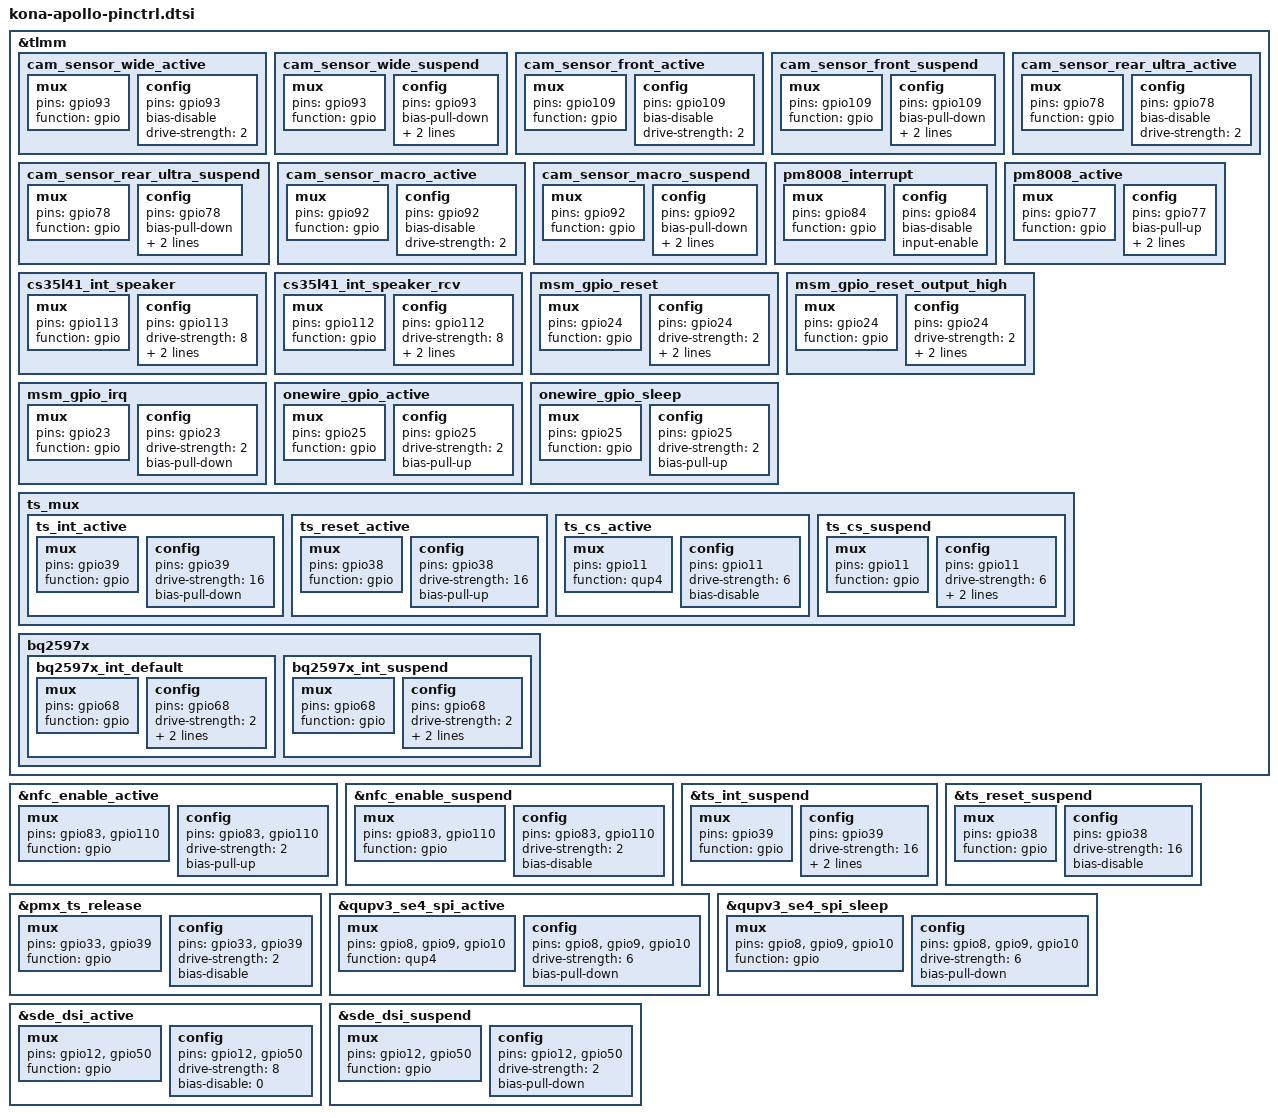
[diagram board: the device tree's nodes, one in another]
// SPDX-License-Identifier: GPL-2.0
/* Copyright (c) 2022, The Linux Foundation. All rights reserved.
 *
 * This program is free software; you can redistribute it and/or modify
 * it under the terms of the GNU General Public License version 2 and
 * only version 2 as published by the Free Software Foundation.
 *
 * This program is distributed in the hope that it will be useful,
 * but WITHOUT ANY WARRANTY; without even the implied warranty of
 * MERCHANTABILITY or FITNESS FOR A PARTICULAR PURPOSE.  See the
 * GNU General Public License for more details.
 */

&tlmm {
	cam_sensor_wide_active: cam_sensor_wide_active {
		/* RESET WIDE */
		mux {
			pins = "gpio93";
			function = "gpio";
		};

		config {
			pins = "gpio93";
			bias-disable; /* No PULL */
			drive-strength = <2>; /* 2 MA */
		};
	};

	cam_sensor_wide_suspend: cam_sensor_wide_suspend {
		mux {
			pins = "gpio93";
			function = "gpio";
		};

		config {
			pins = "gpio93";
			bias-pull-down; /* PULL DOWN */
			drive-strength = <2>; /* 2 MA */
			output-low;
		};
	};

	cam_sensor_front_active: cam_sensor_front_active {
		/* RESET FRONT */
		mux {
			pins = "gpio109";
			function = "gpio";
		};

		config {
			pins = "gpio109";
			bias-disable; /* No PULL */
			drive-strength = <2>; /* 2 MA */
		};
	};

	cam_sensor_front_suspend: cam_sensor_front_suspend {
		mux {
			pins = "gpio109";
			function = "gpio";
		};

		config {
			pins = "gpio109";
			bias-pull-down; /* PULL DOWN */
			drive-strength = <2>; /* 2 MA */
			output-low;
		};
	};

	cam_sensor_rear_ultra_active: cam_sensor_rear_ultra_active {
		/* RESET REAR ULTRA */
		mux {
			pins = "gpio78";
			function = "gpio";
		};

		config {
			pins = "gpio78";
			bias-disable; /* No PULL */
			drive-strength = <2>; /* 2 MA */
		};
	};

	cam_sensor_rear_ultra_suspend: cam_sensor_rear_ultra_suspend {
		mux {
			pins = "gpio78";
			function = "gpio";
		};

		config {
			pins = "gpio78";
			bias-pull-down; /* PULL DOWN */
			drive-strength = <2>; /* 2 MA */
			output-low;
		};
	};

	cam_sensor_macro_active: cam_sensor_macro_active {
		/* RESET MACRO */
		mux {
			pins = "gpio92";
			function = "gpio";
		};

		config {
			pins = "gpio92";
			bias-disable; /* No PULL */
			drive-strength = <2>; /* 2 MA */
		};
	};

	cam_sensor_macro_suspend: cam_sensor_macro_suspend {
		mux {
			pins = "gpio92";
			function = "gpio";
		};

		config {
			pins = "gpio92";
			bias-pull-down; /* PULL DOWN */
			drive-strength = <2>; /* 2 MA */
			output-low;
		};
	};

	pm8008_interrupt: pm8008_interrupt {
		mux {
			pins = "gpio84";
			function = "gpio";
		};

		config {
			pins = "gpio84";
			bias-disable;
			input-enable;
		};
	};

	pm8008_active: pm8008_active {
		mux {
			pins = "gpio77";
			function = "gpio";
		};

		config {
			pins = "gpio77";
			bias-pull-up;
			output-high;
			drive-strength = <2>;
		};
	};

	cs35l41_int_speaker: cs35l41_int_speaker {
		mux {
			pins = "gpio113";
			function = "gpio";
		};
		config {
			pins = "gpio113";
			drive-strength = <8>;   /* 8 mA */
			bias-disable;           /* NO PULL */
			output-high;
		};
	};

	cs35l41_int_speaker_rcv: cs35l41_int_speaker_rcv {
		mux {
			pins = "gpio112";
			function = "gpio";
		};
		config {
			pins = "gpio112";
			drive-strength = <8>;   /* 8 mA */
			bias-disable;           /* NO PULL */
			output-high;
		};
	};

	msm_gpio_reset: msm_gpio_reset {
		mux {
			pins = "gpio24";
			function = "gpio";
		};
		config {
			pins = "gpio24";
			drive-strength = <2>;
			bias-disable;
			output-low;
		};
	};

	msm_gpio_reset_output_high: msm_gpio_reset_output_high {
		mux {
			pins = "gpio24";
			function = "gpio";
		};
		config {
			pins = "gpio24";
			drive-strength = <2>;
			bias-disable;
			output-high;
		};
	};

	msm_gpio_irq: msm_gpio_irq {
		mux {
			pins = "gpio23";
			function = "gpio";
		};
		config {
			pins = "gpio23";
			drive-strength = <2>;
			bias-pull-down;
		};
	};

	onewire_gpio_active: onewire_gpio_active {
		mux {
			pins = "gpio25";
			function = "gpio";
		};

		config {
			pins = "gpio25";
			drive-strength = <2>;
			bias-pull-up; /* No PULL */
		};
	};

	onewire_gpio_sleep: onewire_gpio_sleep {
		mux {
			pins = "gpio25";
			function = "gpio";
		};

		config {
			pins = "gpio25";
			drive-strength = <2>;
			bias-pull-up; /* No PULL */
		};
	};

	ts_mux {
		ts_int_active: ts_int_active {
			mux {
				pins = "gpio39";
				function = "gpio";
			};

			config {
				pins = "gpio39";
				drive-strength = <16>;
				bias-pull-down;
			};
		};

		ts_reset_active: ts_reset_active {
			mux {
				pins = "gpio38";
				function = "gpio";
			};

			config {
				pins = "gpio38";
				drive-strength = <16>;
				bias-pull-up;
			};
		};

		ts_cs_active: ts_cs_active {
			mux {
				pins = "gpio11";
				function = "qup4";
			};

			config {
				pins = "gpio11";
				drive-strength = <6>;
				bias-disable;
			};
		};

		ts_cs_suspend: ts_cs_suspend {
			mux {
				pins = "gpio11";
				function = "gpio";
			};

			config {
				pins = "gpio11";
				drive-strength = <6>;
				bias-pull-down;
				output-low;
			};
		};
	};

	bq2597x {
		bq2597x_int_default: bq2597x_int_default {
			mux {
				pins = "gpio68";
				function = "gpio";
			};

			config {
				pins = "gpio68";
				drive-strength = <2>; /* 2 MA */
				bias-pull-up;
				input-enable;
			};
		};

		bq2597x_int_suspend: bq2597x_int_suspend {
			mux {
				pins = "gpio68";
				function = "gpio";
			};

			config {
				pins = "gpio68";
				drive-strength = <2>; /* 2 MA */
				bias-pull-up;
				input-enable;
			};
		};
	};
};

&nfc_enable_active {
	mux {
		pins = "gpio83", "gpio110";
		function = "gpio";
	};

	config {
		pins = "gpio83", "gpio110";
		drive-strength = <2>;
		bias-pull-up;
	};
};

&nfc_enable_suspend {
	mux {
		pins = "gpio83", "gpio110";
		function = "gpio";
	};

	config {
		pins = "gpio83", "gpio110";
		drive-strength = <2>;
		bias-disable;
	};
};

&ts_int_suspend {
	mux {
		pins = "gpio39";
		function = "gpio";
	};

	config {
		pins = "gpio39";
		drive-strength = <16>;
		bias-disable;
		input-enable;
	};
};

&ts_reset_suspend {
	mux {
		pins = "gpio38";
		function = "gpio";
	};

	config {
		pins = "gpio38";
		drive-strength = <16>;
		bias-disable;
	};
};

&pmx_ts_release {
	mux {
		pins = "gpio33", "gpio39";
		function = "gpio";
	};

	config {
		pins = "gpio33", "gpio39";
		drive-strength = <2>;
		bias-disable;
	};
};

&qupv3_se4_spi_active {
	mux {
		pins = "gpio8", "gpio9", "gpio10";
		function = "qup4";
	};

	config {
		pins = "gpio8", "gpio9", "gpio10";
		drive-strength = <6>;
		bias-pull-down;
	};
};

&qupv3_se4_spi_sleep {
	mux {
		pins = "gpio8", "gpio9", "gpio10";
		function = "gpio";
	};

	config {
		pins = "gpio8", "gpio9", "gpio10";
		drive-strength = <6>;
		bias-pull-down;
	};
};

&sde_dsi_active {
	mux {
		pins = "gpio12", "gpio50";
		function = "gpio";
	};

	config {
		pins = "gpio12", "gpio50";
		drive-strength = <8>;	/* 8 mA */
		bias-disable = <0>;   /* no pull */
	};
};

&sde_dsi_suspend {
	mux {
		pins = "gpio12", "gpio50";
		function = "gpio";
	};

	config {
		pins = "gpio12", "gpio50";
		drive-strength = <2>;	/* 2 mA */
		bias-pull-down; 		/* PULL DOWN */
	};
};
